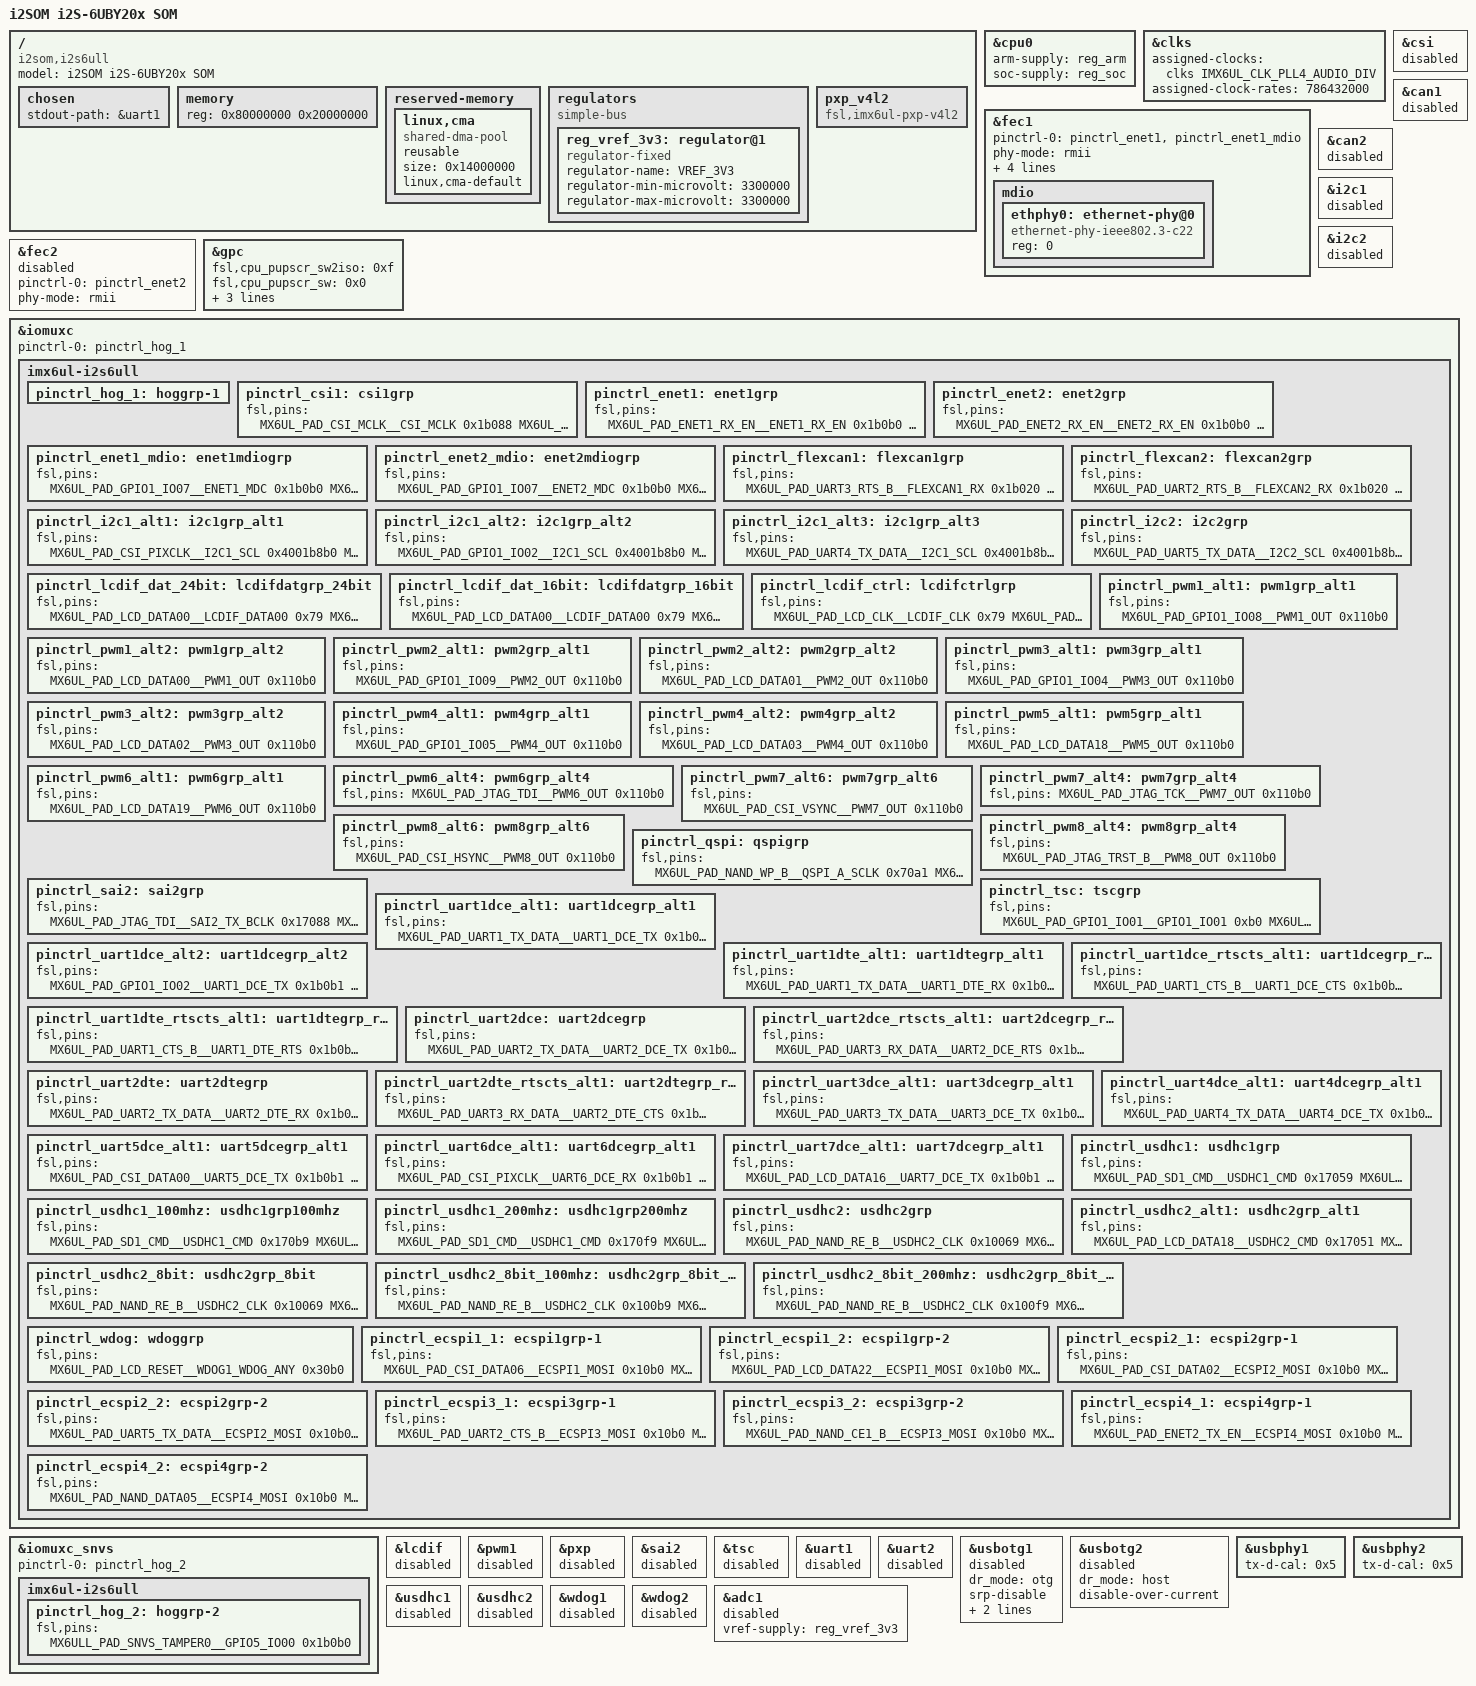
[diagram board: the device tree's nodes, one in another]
/*
 * Copyright (C) 2016 Freescale Semiconductor, Inc.
 *
 * This program is free software; you can redistribute it and/or modify
 * it under the terms of the GNU General Public License version 2 as
 * published by the Free Software Foundation.
 */

/ {
	model = "i2SOM i2S-6UBY20x SOM";
	compatible = "i2som,i2s6ull", "i2som,i2s6ull14x14", "fsl,imx6ull";

	chosen {
		stdout-path = &uart1;
	};

	memory {
		reg = <0x80000000 0x20000000>;
	};

	reserved-memory {
		#address-cells = <1>;
		#size-cells = <1>;
		ranges;

		linux,cma {
			compatible = "shared-dma-pool";
			reusable;
			size = <0x14000000>;
			linux,cma-default;
		};
	};

	regulators:regulators {
		compatible = "simple-bus";
		#address-cells = <1>;
		#size-cells = <0>;

		reg_vref_3v3: regulator@1 {
			compatible = "regulator-fixed";
			regulator-name = "VREF_3V3";
			regulator-min-microvolt = <3300000>;
			regulator-max-microvolt = <3300000>;
		};
	};

	pxp_v4l2 {
		compatible = "fsl,imx6ul-pxp-v4l2", "fsl,imx6sx-pxp-v4l2", "fsl,imx6sl-pxp-v4l2";
		status = "okay";
	};
};

&cpu0 {
	arm-supply = <&reg_arm>;
	soc-supply = <&reg_soc>;
};

&clks {
	assigned-clocks = <&clks IMX6UL_CLK_PLL4_AUDIO_DIV>;
	assigned-clock-rates = <786432000>;
};

&csi {
	status = "disabled";
};

&fec1 {
	pinctrl-names = "default";
	pinctrl-0 = <&pinctrl_enet1 &pinctrl_enet1_mdio>;
	phy-mode = "rmii";
	phy-handle = <&ethphy0>;
	phy-reset-gpios = <&gpio5 0 GPIO_ACTIVE_LOW>;
	phy-reset-duration = <50>;
	phy-reset-post-delay = <50>;
	status = "okay";

	mdio {
		#address-cells = <1>;
		#size-cells = <0>;

		ethphy0: ethernet-phy@0 {
			compatible = "ethernet-phy-ieee802.3-c22";
			reg = <0>;
		};
	};
};

&fec2 {
	pinctrl-names = "default";
	pinctrl-0 = <&pinctrl_enet2>;
	phy-mode = "rmii";
	status = "disabled";
};

&can1 {
	status = "disabled";
};

&can2 {
	status = "disabled";
};

&gpc {
	fsl,cpu_pupscr_sw2iso = <0xf>;
	fsl,cpu_pupscr_sw = <0x0>;
	fsl,cpu_pdnscr_iso2sw = <0x1>;
	fsl,cpu_pdnscr_iso = <0x1>;
	fsl,ldo-bypass = <0>; /* DCDC, ldo-enable */
};

&i2c1 {
	status = "disabled";
};

&i2c2 {
	status = "disabled";
};

&iomuxc {
	pinctrl-names = "default";
	pinctrl-0 = <&pinctrl_hog_1>;
	imx6ul-i2s6ull {
		pinctrl_hog_1: hoggrp-1 {
		};

		pinctrl_csi1: csi1grp {
			fsl,pins = <
				MX6UL_PAD_CSI_MCLK__CSI_MCLK		0x1b088
				MX6UL_PAD_CSI_PIXCLK__CSI_PIXCLK	0x1b088
				MX6UL_PAD_CSI_VSYNC__CSI_VSYNC		0x1b088
				MX6UL_PAD_CSI_HSYNC__CSI_HSYNC		0x1b088
				MX6UL_PAD_CSI_DATA00__CSI_DATA02	0x1b088
				MX6UL_PAD_CSI_DATA01__CSI_DATA03	0x1b088
				MX6UL_PAD_CSI_DATA02__CSI_DATA04	0x1b088
				MX6UL_PAD_CSI_DATA03__CSI_DATA05	0x1b088
				MX6UL_PAD_CSI_DATA04__CSI_DATA06	0x1b088
				MX6UL_PAD_CSI_DATA05__CSI_DATA07	0x1b088
				MX6UL_PAD_CSI_DATA06__CSI_DATA08	0x1b088
				MX6UL_PAD_CSI_DATA07__CSI_DATA09	0x1b088
			>;
		};

		pinctrl_enet1: enet1grp {
			fsl,pins = <
				MX6UL_PAD_ENET1_RX_EN__ENET1_RX_EN	0x1b0b0
				MX6UL_PAD_ENET1_RX_ER__ENET1_RX_ER	0x1b0b0
				MX6UL_PAD_ENET1_RX_DATA0__ENET1_RDATA00	0x1b0b0
				MX6UL_PAD_ENET1_RX_DATA1__ENET1_RDATA01	0x1b0b0
				MX6UL_PAD_ENET1_TX_EN__ENET1_TX_EN	0x1b0b0
				MX6UL_PAD_ENET1_TX_DATA0__ENET1_TDATA00	0x1b0b0
				MX6UL_PAD_ENET1_TX_DATA1__ENET1_TDATA01	0x1b0b0
				MX6UL_PAD_ENET1_TX_CLK__ENET1_REF_CLK1	0x4001b031
			>;
		};

		pinctrl_enet2: enet2grp {
			fsl,pins = <
				MX6UL_PAD_ENET2_RX_EN__ENET2_RX_EN	0x1b0b0
				MX6UL_PAD_ENET2_RX_ER__ENET2_RX_ER	0x1b0b0
				MX6UL_PAD_ENET2_RX_DATA0__ENET2_RDATA00	0x1b0b0
				MX6UL_PAD_ENET2_RX_DATA1__ENET2_RDATA01	0x1b0b0
				MX6UL_PAD_ENET2_TX_EN__ENET2_TX_EN	0x1b0b0
				MX6UL_PAD_ENET2_TX_DATA0__ENET2_TDATA00	0x1b0b0
				MX6UL_PAD_ENET2_TX_DATA1__ENET2_TDATA01	0x1b0b0
				MX6UL_PAD_ENET2_TX_CLK__ENET2_REF_CLK2	0x4001b031
			>;
		};

		pinctrl_enet1_mdio: enet1mdiogrp {
			fsl,pins = <
				MX6UL_PAD_GPIO1_IO07__ENET1_MDC		0x1b0b0
				MX6UL_PAD_GPIO1_IO06__ENET1_MDIO	0x1b0b0
			>;
		};

		pinctrl_enet2_mdio: enet2mdiogrp {
			fsl,pins = <
				MX6UL_PAD_GPIO1_IO07__ENET2_MDC		0x1b0b0
				MX6UL_PAD_GPIO1_IO06__ENET2_MDIO	0x1b0b0
			>;
		};

		pinctrl_flexcan1: flexcan1grp{
			fsl,pins = <
				MX6UL_PAD_UART3_RTS_B__FLEXCAN1_RX	0x1b020
				MX6UL_PAD_UART3_CTS_B__FLEXCAN1_TX	0x1b020
			>;
		};

		pinctrl_flexcan2: flexcan2grp{
			fsl,pins = <
				MX6UL_PAD_UART2_RTS_B__FLEXCAN2_RX	0x1b020
				MX6UL_PAD_UART2_CTS_B__FLEXCAN2_TX	0x1b020
			>;
		};

		pinctrl_i2c1_alt1: i2c1grp_alt1 {
			fsl,pins = <
				MX6UL_PAD_CSI_PIXCLK__I2C1_SCL		0x4001b8b0
				MX6UL_PAD_CSI_MCLK__I2C1_SDA		0x4001b8b0
			>;
		};

		pinctrl_i2c1_alt2: i2c1grp_alt2 {
			fsl,pins = <
				MX6UL_PAD_GPIO1_IO02__I2C1_SCL		0x4001b8b0
				MX6UL_PAD_GPIO1_IO03__I2C1_SDA		0x4001b8b0
			>;
		};

		pinctrl_i2c1_alt3: i2c1grp_alt3 {
			fsl,pins = <
				MX6UL_PAD_UART4_TX_DATA__I2C1_SCL	0x4001b8b0
				MX6UL_PAD_UART4_RX_DATA__I2C1_SDA	0x4001b8b0
			>;
		};

		pinctrl_i2c2: i2c2grp {
			fsl,pins = <
				MX6UL_PAD_UART5_TX_DATA__I2C2_SCL 0x4001b8b0
				MX6UL_PAD_UART5_RX_DATA__I2C2_SDA 0x4001b8b0
			>;
		};

		pinctrl_lcdif_dat_24bit: lcdifdatgrp_24bit {
			fsl,pins = <
				MX6UL_PAD_LCD_DATA00__LCDIF_DATA00  0x79
				MX6UL_PAD_LCD_DATA01__LCDIF_DATA01  0x79
				MX6UL_PAD_LCD_DATA02__LCDIF_DATA02  0x79
				MX6UL_PAD_LCD_DATA03__LCDIF_DATA03  0x79
				MX6UL_PAD_LCD_DATA04__LCDIF_DATA04  0x79
				MX6UL_PAD_LCD_DATA05__LCDIF_DATA05  0x79
				MX6UL_PAD_LCD_DATA06__LCDIF_DATA06  0x79
				MX6UL_PAD_LCD_DATA07__LCDIF_DATA07  0x79
				MX6UL_PAD_LCD_DATA08__LCDIF_DATA08  0x79
				MX6UL_PAD_LCD_DATA09__LCDIF_DATA09  0x79
				MX6UL_PAD_LCD_DATA10__LCDIF_DATA10  0x79
				MX6UL_PAD_LCD_DATA11__LCDIF_DATA11  0x79
				MX6UL_PAD_LCD_DATA12__LCDIF_DATA12  0x79
				MX6UL_PAD_LCD_DATA13__LCDIF_DATA13  0x79
				MX6UL_PAD_LCD_DATA14__LCDIF_DATA14  0x79
				MX6UL_PAD_LCD_DATA15__LCDIF_DATA15  0x79
				MX6UL_PAD_LCD_DATA16__LCDIF_DATA16  0x79
				MX6UL_PAD_LCD_DATA17__LCDIF_DATA17  0x79
				MX6UL_PAD_LCD_DATA18__LCDIF_DATA18  0x79
				MX6UL_PAD_LCD_DATA19__LCDIF_DATA19  0x79
				MX6UL_PAD_LCD_DATA20__LCDIF_DATA20  0x79
				MX6UL_PAD_LCD_DATA21__LCDIF_DATA21  0x79
				MX6UL_PAD_LCD_DATA22__LCDIF_DATA22  0x79
				MX6UL_PAD_LCD_DATA23__LCDIF_DATA23  0x79
			>;
		};

		pinctrl_lcdif_dat_16bit: lcdifdatgrp_16bit {
			fsl,pins = <
				MX6UL_PAD_LCD_DATA00__LCDIF_DATA00  0x79
				MX6UL_PAD_LCD_DATA01__LCDIF_DATA01  0x79
				MX6UL_PAD_LCD_DATA02__LCDIF_DATA02  0x79
				MX6UL_PAD_LCD_DATA03__LCDIF_DATA03  0x79
				MX6UL_PAD_LCD_DATA04__LCDIF_DATA04  0x79
				MX6UL_PAD_LCD_DATA05__LCDIF_DATA05  0x79
				MX6UL_PAD_LCD_DATA06__LCDIF_DATA06  0x79
				MX6UL_PAD_LCD_DATA07__LCDIF_DATA07  0x79
				MX6UL_PAD_LCD_DATA08__LCDIF_DATA08  0x79
				MX6UL_PAD_LCD_DATA09__LCDIF_DATA09  0x79
				MX6UL_PAD_LCD_DATA10__LCDIF_DATA10  0x79
				MX6UL_PAD_LCD_DATA11__LCDIF_DATA11  0x79
				MX6UL_PAD_LCD_DATA12__LCDIF_DATA12  0x79
				MX6UL_PAD_LCD_DATA13__LCDIF_DATA13  0x79
				MX6UL_PAD_LCD_DATA14__LCDIF_DATA14  0x79
				MX6UL_PAD_LCD_DATA15__LCDIF_DATA15  0x79
			>;
		};

		pinctrl_lcdif_ctrl: lcdifctrlgrp {
			fsl,pins = <
				MX6UL_PAD_LCD_CLK__LCDIF_CLK	    0x79
				MX6UL_PAD_LCD_ENABLE__LCDIF_ENABLE  0x79
				MX6UL_PAD_LCD_HSYNC__LCDIF_HSYNC    0x79
				MX6UL_PAD_LCD_VSYNC__LCDIF_VSYNC    0x79
			>;
		};

		pinctrl_pwm1_alt1: pwm1grp_alt1 {
			fsl,pins = <
				MX6UL_PAD_GPIO1_IO08__PWM1_OUT		0x110b0
			>;
		};

		pinctrl_pwm1_alt2: pwm1grp_alt2 {
			fsl,pins = <
				MX6UL_PAD_LCD_DATA00__PWM1_OUT		0x110b0
			>;
		};

		pinctrl_pwm2_alt1: pwm2grp_alt1 {
			fsl,pins = <
				MX6UL_PAD_GPIO1_IO09__PWM2_OUT		0x110b0
			>;
		};

		pinctrl_pwm2_alt2: pwm2grp_alt2 {
			fsl,pins = <
				MX6UL_PAD_LCD_DATA01__PWM2_OUT		0x110b0
			>;
		};

		pinctrl_pwm3_alt1: pwm3grp_alt1 {
			fsl,pins = <
				MX6UL_PAD_GPIO1_IO04__PWM3_OUT		0x110b0
			>;
		};

		pinctrl_pwm3_alt2: pwm3grp_alt2 {
			fsl,pins = <
				MX6UL_PAD_LCD_DATA02__PWM3_OUT		0x110b0
			>;
		};

		pinctrl_pwm4_alt1: pwm4grp_alt1 {
			fsl,pins = <
				MX6UL_PAD_GPIO1_IO05__PWM4_OUT		0x110b0
			>;
		};

		pinctrl_pwm4_alt2: pwm4grp_alt2 {
			fsl,pins = <
				MX6UL_PAD_LCD_DATA03__PWM4_OUT		0x110b0
			>;
		};

		pinctrl_pwm5_alt1: pwm5grp_alt1 {
			fsl,pins = <
				MX6UL_PAD_LCD_DATA18__PWM5_OUT		0x110b0
			>;
		};

		pinctrl_pwm6_alt1: pwm6grp_alt1 {
			fsl,pins = <
				MX6UL_PAD_LCD_DATA19__PWM6_OUT		0x110b0
			>;
		};

		pinctrl_pwm6_alt4: pwm6grp_alt4 {
			fsl,pins = <
				MX6UL_PAD_JTAG_TDI__PWM6_OUT		0x110b0
			>;
		};

		pinctrl_pwm7_alt6: pwm7grp_alt6 {
			fsl,pins = <
				MX6UL_PAD_CSI_VSYNC__PWM7_OUT		0x110b0
			>;
		};

		pinctrl_pwm7_alt4: pwm7grp_alt4 {
			fsl,pins = <
				MX6UL_PAD_JTAG_TCK__PWM7_OUT		0x110b0
			>;
		};

		pinctrl_pwm8_alt6: pwm8grp_alt6 {
			fsl,pins = <
				MX6UL_PAD_CSI_HSYNC__PWM8_OUT		0x110b0
			>;
		};

		pinctrl_pwm8_alt4: pwm8grp_alt4 {
			fsl,pins = <
				MX6UL_PAD_JTAG_TRST_B__PWM8_OUT		0x110b0
			>;
		};

		pinctrl_qspi: qspigrp {
			fsl,pins = <
				MX6UL_PAD_NAND_WP_B__QSPI_A_SCLK      0x70a1
				MX6UL_PAD_NAND_READY_B__QSPI_A_DATA00 0x70a1
				MX6UL_PAD_NAND_CE0_B__QSPI_A_DATA01   0x70a1
				MX6UL_PAD_NAND_CE1_B__QSPI_A_DATA02   0x70a1
				MX6UL_PAD_NAND_CLE__QSPI_A_DATA03     0x70a1
				MX6UL_PAD_NAND_DQS__QSPI_A_SS0_B      0x70a1
			>;
		};

		pinctrl_sai2: sai2grp {
			fsl,pins = <
				MX6UL_PAD_JTAG_TDI__SAI2_TX_BCLK	0x17088
				MX6UL_PAD_JTAG_TDO__SAI2_TX_SYNC	0x17088
				MX6UL_PAD_JTAG_TRST_B__SAI2_TX_DATA	0x11088
				MX6UL_PAD_JTAG_TCK__SAI2_RX_DATA	0x11088
				MX6UL_PAD_JTAG_TMS__SAI2_MCLK		0x17088
			>;
		};

		pinctrl_tsc: tscgrp {
			fsl,pins = <
				MX6UL_PAD_GPIO1_IO01__GPIO1_IO01	0xb0
				MX6UL_PAD_GPIO1_IO02__GPIO1_IO02	0xb0
				MX6UL_PAD_GPIO1_IO03__GPIO1_IO03	0xb0
				MX6UL_PAD_GPIO1_IO04__GPIO1_IO04	0xb0
			>;
		};

		pinctrl_uart1dce_alt1: uart1dcegrp_alt1 {
			fsl,pins = <
				MX6UL_PAD_UART1_TX_DATA__UART1_DCE_TX 0x1b0b1
				MX6UL_PAD_UART1_RX_DATA__UART1_DCE_RX 0x1b0b1
			>;
		};

		pinctrl_uart1dce_alt2: uart1dcegrp_alt2 {
			fsl,pins = <
				MX6UL_PAD_GPIO1_IO02__UART1_DCE_TX 0x1b0b1
				MX6UL_PAD_GPIO1_IO03__UART1_DCE_RX 0x1b0b1
			>;
		};

		pinctrl_uart1dte_alt1: uart1dtegrp_alt1 {
			fsl,pins = <
				MX6UL_PAD_UART1_TX_DATA__UART1_DTE_RX 0x1b0b1
				MX6UL_PAD_UART1_RX_DATA__UART1_DTE_TX 0x1b0b1
			>;
		};

		pinctrl_uart1dce_rtscts_alt1: uart1dcegrp_rtscts_alt1 {
			fsl,pins = <
				MX6UL_PAD_UART1_CTS_B__UART1_DCE_CTS 0x1b0b1
				MX6UL_PAD_UART1_RTS_B__UART1_DCE_RTS 0x1b0b1
			>;
		};

		pinctrl_uart1dte_rtscts_alt1: uart1dtegrp_rtscts_alt1 {
			fsl,pins = <
				MX6UL_PAD_UART1_CTS_B__UART1_DTE_RTS 0x1b0b1
				MX6UL_PAD_UART1_RTS_B__UART1_DTE_CTS 0x1b0b1
			>;
		};

		pinctrl_uart2dce: uart2dcegrp {
			fsl,pins = <
				MX6UL_PAD_UART2_TX_DATA__UART2_DCE_TX	0x1b0b1
				MX6UL_PAD_UART2_RX_DATA__UART2_DCE_RX	0x1b0b1
			>;
		};

		pinctrl_uart2dce_rtscts_alt1: uart2dcegrp_rtscts_alt1 {
			fsl,pins = <
				MX6UL_PAD_UART3_RX_DATA__UART2_DCE_RTS	0x1b0b1
				MX6UL_PAD_UART3_TX_DATA__UART2_DCE_CTS	0x1b0b1
			>;
		};

		pinctrl_uart2dte: uart2dtegrp {
			fsl,pins = <
				MX6UL_PAD_UART2_TX_DATA__UART2_DTE_RX	0x1b0b1
				MX6UL_PAD_UART2_RX_DATA__UART2_DTE_TX	0x1b0b1
			>;
		};

		pinctrl_uart2dte_rtscts_alt1: uart2dtegrp_rtscts_alt1 {
			fsl,pins = <
				MX6UL_PAD_UART3_RX_DATA__UART2_DTE_CTS	0x1b0b1
				MX6UL_PAD_UART3_TX_DATA__UART2_DTE_RTS	0x1b0b1
			>;
		};

		pinctrl_uart3dce_alt1: uart3dcegrp_alt1 {
			fsl,pins = <
				MX6UL_PAD_UART3_TX_DATA__UART3_DCE_TX	0x1b0b1
				MX6UL_PAD_UART3_RX_DATA__UART3_DCE_RX	0x1b0b1
			>;
		};

		pinctrl_uart4dce_alt1: uart4dcegrp_alt1 {
			fsl,pins = <
				MX6UL_PAD_UART4_TX_DATA__UART4_DCE_TX	0x1b0b1
				MX6UL_PAD_UART4_RX_DATA__UART4_DCE_RX	0x1b0b1
			>;
		};

		pinctrl_uart5dce_alt1: uart5dcegrp_alt1 {
			fsl,pins = <
				MX6UL_PAD_CSI_DATA00__UART5_DCE_TX	0x1b0b1
				MX6UL_PAD_CSI_DATA01__UART5_DCE_RX	0x1b0b1
			>;
		};

		pinctrl_uart6dce_alt1: uart6dcegrp_alt1 {
			fsl,pins = <
				MX6UL_PAD_CSI_PIXCLK__UART6_DCE_RX	0x1b0b1
				MX6UL_PAD_CSI_MCLK__UART6_DCE_TX	0x1b0b1
			>;
		};

		pinctrl_uart7dce_alt1: uart7dcegrp_alt1 {
			fsl,pins = <
				MX6UL_PAD_LCD_DATA16__UART7_DCE_TX	0x1b0b1
				MX6UL_PAD_LCD_DATA17__UART7_DCE_RX	0x1b0b1
			>;
		};

		pinctrl_usdhc1: usdhc1grp {
			fsl,pins = <
				MX6UL_PAD_SD1_CMD__USDHC1_CMD     0x17059
				MX6UL_PAD_SD1_CLK__USDHC1_CLK     0x10071
				MX6UL_PAD_SD1_DATA0__USDHC1_DATA0 0x17059
				MX6UL_PAD_SD1_DATA1__USDHC1_DATA1 0x17059
				MX6UL_PAD_SD1_DATA2__USDHC1_DATA2 0x17059
				MX6UL_PAD_SD1_DATA3__USDHC1_DATA3 0x17059
			>;
		};

		pinctrl_usdhc1_100mhz: usdhc1grp100mhz {
			fsl,pins = <
				MX6UL_PAD_SD1_CMD__USDHC1_CMD     0x170b9
				MX6UL_PAD_SD1_CLK__USDHC1_CLK     0x100b9
				MX6UL_PAD_SD1_DATA0__USDHC1_DATA0 0x170b9
				MX6UL_PAD_SD1_DATA1__USDHC1_DATA1 0x170b9
				MX6UL_PAD_SD1_DATA2__USDHC1_DATA2 0x170b9
				MX6UL_PAD_SD1_DATA3__USDHC1_DATA3 0x170b9
			>;
		};

		pinctrl_usdhc1_200mhz: usdhc1grp200mhz {
			fsl,pins = <
				MX6UL_PAD_SD1_CMD__USDHC1_CMD     0x170f9
				MX6UL_PAD_SD1_CLK__USDHC1_CLK     0x100f9
				MX6UL_PAD_SD1_DATA0__USDHC1_DATA0 0x170f9
				MX6UL_PAD_SD1_DATA1__USDHC1_DATA1 0x170f9
				MX6UL_PAD_SD1_DATA2__USDHC1_DATA2 0x170f9
				MX6UL_PAD_SD1_DATA3__USDHC1_DATA3 0x170f9
			>;
		};

		pinctrl_usdhc2: usdhc2grp {
			fsl,pins = <
				MX6UL_PAD_NAND_RE_B__USDHC2_CLK     0x10069
				MX6UL_PAD_NAND_WE_B__USDHC2_CMD     0x17059
				MX6UL_PAD_NAND_DATA00__USDHC2_DATA0 0x17059
				MX6UL_PAD_NAND_DATA01__USDHC2_DATA1 0x17059
				MX6UL_PAD_NAND_DATA02__USDHC2_DATA2 0x17059
				MX6UL_PAD_NAND_DATA03__USDHC2_DATA3 0x17059
			>;
		};

		pinctrl_usdhc2_alt1: usdhc2grp_alt1 {
			fsl,pins = <
				MX6UL_PAD_LCD_DATA18__USDHC2_CMD    0x17051
				MX6UL_PAD_LCD_DATA19__USDHC2_CLK    0x17051
				MX6UL_PAD_LCD_DATA20__USDHC2_DATA0  0x17051
				MX6UL_PAD_LCD_DATA21__USDHC2_DATA1  0x17051
				MX6UL_PAD_LCD_DATA22__USDHC2_DATA2  0x17051
				MX6UL_PAD_LCD_DATA23__USDHC2_DATA3  0x17051
			>;
		};

		pinctrl_usdhc2_8bit: usdhc2grp_8bit {
			fsl,pins = <
				MX6UL_PAD_NAND_RE_B__USDHC2_CLK     0x10069
				MX6UL_PAD_NAND_WE_B__USDHC2_CMD     0x17059
				MX6UL_PAD_NAND_DATA00__USDHC2_DATA0 0x17059
				MX6UL_PAD_NAND_DATA01__USDHC2_DATA1 0x17059
				MX6UL_PAD_NAND_DATA02__USDHC2_DATA2 0x17059
				MX6UL_PAD_NAND_DATA03__USDHC2_DATA3 0x17059
				MX6UL_PAD_NAND_DATA04__USDHC2_DATA4 0x17059
				MX6UL_PAD_NAND_DATA05__USDHC2_DATA5 0x17059
				MX6UL_PAD_NAND_DATA06__USDHC2_DATA6 0x17059
				MX6UL_PAD_NAND_DATA07__USDHC2_DATA7 0x17059
			>;
		};

		pinctrl_usdhc2_8bit_100mhz: usdhc2grp_8bit_100mhz {
			fsl,pins = <
				MX6UL_PAD_NAND_RE_B__USDHC2_CLK     0x100b9
				MX6UL_PAD_NAND_WE_B__USDHC2_CMD     0x170b9
				MX6UL_PAD_NAND_DATA00__USDHC2_DATA0 0x170b9
				MX6UL_PAD_NAND_DATA01__USDHC2_DATA1 0x170b9
				MX6UL_PAD_NAND_DATA02__USDHC2_DATA2 0x170b9
				MX6UL_PAD_NAND_DATA03__USDHC2_DATA3 0x170b9
				MX6UL_PAD_NAND_DATA04__USDHC2_DATA4 0x170b9
				MX6UL_PAD_NAND_DATA05__USDHC2_DATA5 0x170b9
				MX6UL_PAD_NAND_DATA06__USDHC2_DATA6 0x170b9
				MX6UL_PAD_NAND_DATA07__USDHC2_DATA7 0x170b9
			>;
		};

		pinctrl_usdhc2_8bit_200mhz: usdhc2grp_8bit_200mhz {
			fsl,pins = <
				MX6UL_PAD_NAND_RE_B__USDHC2_CLK     0x100f9
				MX6UL_PAD_NAND_WE_B__USDHC2_CMD     0x170f9
				MX6UL_PAD_NAND_DATA00__USDHC2_DATA0 0x170f9
				MX6UL_PAD_NAND_DATA01__USDHC2_DATA1 0x170f9
				MX6UL_PAD_NAND_DATA02__USDHC2_DATA2 0x170f9
				MX6UL_PAD_NAND_DATA03__USDHC2_DATA3 0x170f9
				MX6UL_PAD_NAND_DATA04__USDHC2_DATA4 0x170f9
				MX6UL_PAD_NAND_DATA05__USDHC2_DATA5 0x170f9
				MX6UL_PAD_NAND_DATA06__USDHC2_DATA6 0x170f9
				MX6UL_PAD_NAND_DATA07__USDHC2_DATA7 0x170f9
			>;
		};

		pinctrl_wdog: wdoggrp {
			fsl,pins = <
				MX6UL_PAD_LCD_RESET__WDOG1_WDOG_ANY    0x30b0
			>;
		};

		pinctrl_ecspi1_1: ecspi1grp-1 {
			fsl,pins = <
				MX6UL_PAD_CSI_DATA06__ECSPI1_MOSI 0x10b0
				MX6UL_PAD_CSI_DATA07__ECSPI1_MISO 0x10b0
				MX6UL_PAD_CSI_DATA04__ECSPI1_SCLK 0x10b0
			>;
		};

		pinctrl_ecspi1_2: ecspi1grp-2 {
			fsl,pins = <
				MX6UL_PAD_LCD_DATA22__ECSPI1_MOSI 0x10b0
				MX6UL_PAD_LCD_DATA23__ECSPI1_MISO 0x10b0
				MX6UL_PAD_LCD_DATA20__ECSPI1_SCLK 0x10b0
			>;
		};

		pinctrl_ecspi2_1: ecspi2grp-1 {
			fsl,pins = <
				MX6UL_PAD_CSI_DATA02__ECSPI2_MOSI 0x10b0
				MX6UL_PAD_CSI_DATA03__ECSPI2_MISO 0x10b0
				MX6UL_PAD_CSI_DATA00__ECSPI2_SCLK 0x10b0
			>;
		};

		pinctrl_ecspi2_2: ecspi2grp-2 {
			fsl,pins = <
				MX6UL_PAD_UART5_TX_DATA__ECSPI2_MOSI 0x10b0
				MX6UL_PAD_UART5_RX_DATA__ECSPI2_MISO 0x10b0
				MX6UL_PAD_UART4_TX_DATA__ECSPI2_SCLK 0x10b0
			>;
		};

		pinctrl_ecspi3_1: ecspi3grp-1 {
			fsl,pins = <
				MX6UL_PAD_UART2_CTS_B__ECSPI3_MOSI 0x10b0
				MX6UL_PAD_UART2_RTS_B__ECSPI3_MISO 0x10b0
				MX6UL_PAD_UART2_RX_DATA__ECSPI3_SCLK 0x10b0
			>;
		};

		pinctrl_ecspi3_2: ecspi3grp-2 {
			fsl,pins = <
				MX6UL_PAD_NAND_CE1_B__ECSPI3_MOSI 0x10b0
				MX6UL_PAD_NAND_CLE__ECSPI3_MISO 0x10b0
				MX6UL_PAD_NAND_CE0_B__ECSPI3_SCLK 0x10b0
			>;
		};

		pinctrl_ecspi4_1: ecspi4grp-1 {
			fsl,pins = <
				MX6UL_PAD_ENET2_TX_EN__ECSPI4_MOSI 0x10b0
				MX6UL_PAD_ENET2_TX_CLK__ECSPI4_MISO 0x10b0
				MX6UL_PAD_ENET2_TX_DATA1__ECSPI4_SCLK 0x10b0
			>;
		};

		pinctrl_ecspi4_2: ecspi4grp-2 {
			fsl,pins = <
				MX6UL_PAD_NAND_DATA05__ECSPI4_MOSI 0x10b0
				MX6UL_PAD_NAND_DATA06__ECSPI4_MISO 0x10b0
				MX6UL_PAD_NAND_DATA04__ECSPI4_SCLK 0x10b0
			>;
		};

	};
};

&iomuxc_snvs {
        pinctrl-names = "default_snvs";
        pinctrl-0 = <&pinctrl_hog_2>;
        imx6ul-i2s6ull {
		pinctrl_hog_2: hoggrp-2 {
			fsl,pins = <
				MX6ULL_PAD_SNVS_TAMPER0__GPIO5_IO00      0x1b0b0
			>;
		};
	};
};


&lcdif {
	status = "disabled";
};

&pwm1 {
	status = "disabled";
};

&pxp {
	status = "disabled";
};

&sai2 {
	status = "disabled";
};

&tsc {
	status = "disabled";
};

&uart1 {
	status = "disabled";
};

&uart2 {
	status = "disabled";
};

&usbotg1 {
	dr_mode = "otg";
	srp-disable;
	hnp-disable;
	adp-disable;
	status = "disabled";
};

&usbotg2 {
	dr_mode = "host";
	disable-over-current;
	status = "disabled";
};

&usbphy1 {
	tx-d-cal = <0x5>;
};

&usbphy2 {
	tx-d-cal = <0x5>;
};

&usdhc1 {
	status = "disabled";
};

&usdhc2 {
	status = "disabled";
};

&wdog1 {
	status = "disabled";
};

&wdog2 {
	status = "disabled";
};

&adc1 {
	vref-supply = <&reg_vref_3v3>;
	status = "disabled";
};
